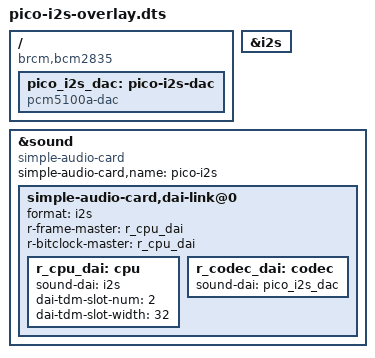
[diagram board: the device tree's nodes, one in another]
// Device tree overlay for Pico I2S Audio
// Based on Pimoroni Audio Pack pin configuration
/dts-v1/;
/plugin/;

/ {
    compatible = "brcm,bcm2835";

    fragment@0 {
        target = <&i2s>;
        __overlay__ {
            status = "okay";
        };
    };

    fragment@1 {
        target-path = "/";
        __overlay__ {
            pico_i2s_dac: pico-i2s-dac {
                #sound-dai-cells = <0>;
                compatible = "pcm5100a-dac";
                status = "okay";
            };
        };
    };

    fragment@2 {
        target = <&sound>;
        __overlay__ {
            compatible = "simple-audio-card";
            simple-audio-card,name = "pico-i2s";
            status = "okay";

            simple-audio-card,dai-link@0 {
                format = "i2s";
                r-frame-master = <&r_cpu_dai>;
                r-bitclock-master = <&r_cpu_dai>;
                
                r_cpu_dai: cpu {
                    sound-dai = <&i2s>;
                    dai-tdm-slot-num = <2>;
                    dai-tdm-slot-width = <32>;
                };
                
                r_codec_dai: codec {
                    sound-dai = <&pico_i2s_dac>;
                };
            };
        };
    };

    __overrides__ {
        i2s_pins = <&i2s>,"brcm,pins:0";
    };
};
